# SAM9X60 device description
Architecture: ARM926EJS; Family: SAM9; Series: SAM9X
Registers are 32-bit, read-write, no defined reset value unless marked. A register's access mark holds for its fields unless they carry their own. Offsets are from the block's base; [hi:lo] are bit positions.

## SYSCWP — External Interrupt Controller
Instances: SYSCWP 0xFFFFFEDC
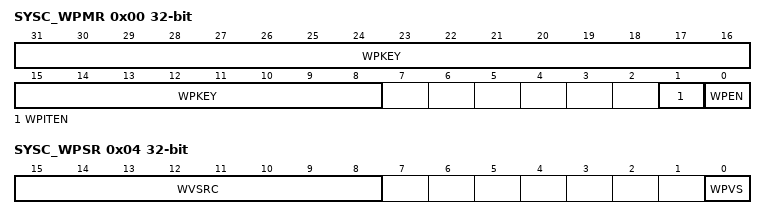
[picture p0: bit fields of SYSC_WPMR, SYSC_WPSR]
0x00 SYSC_WPMR — Write Protection Mode Register
  [31:8] WPKEY — Write Protection Key
    0x535943=PASSWD (Writing any other value in this field aborts the write operation of the WPEN and WPITEN bits. Always reads as 0.)
  [1] WPITEN — Write Protection RTC Interrupt Enable
  [0] WPEN — Write Protection Enable
0x04 SYSC_WPSR ro — Write Protection Status Register
  [15:8] WVSRC — Write Violation Source
  [0] WPVS — Write Protection Register Violation Status

## TRNG — True Random Number Generator
Instances: TRNG 0xF0030000
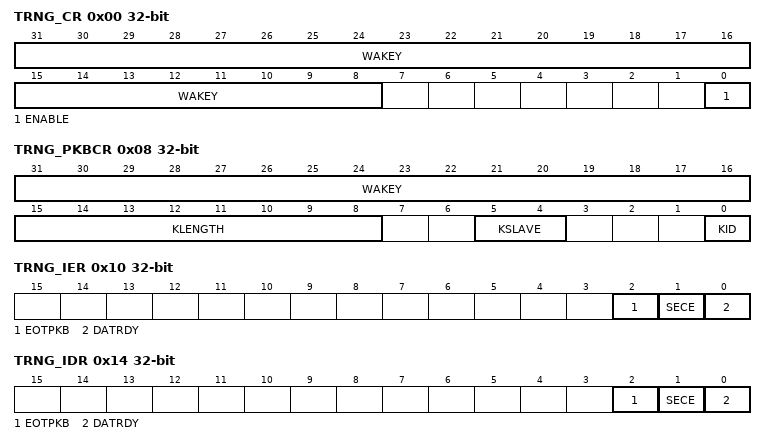
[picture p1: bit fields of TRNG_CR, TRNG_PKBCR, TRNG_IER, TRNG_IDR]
0x00 TRNG_CR wo — Control Register
  [31:8] WAKEY — Register Write Access Key
    0x524E47=PASSWD (Writing any other value in this field aborts the write operation.)
  [0] ENABLE — Enable TRNG to Provide Random Values
0x04 TRNG_MR — Mode Register
  [0] HALFR — Half Rate Enable
0x08 TRNG_PKBCR wo — Private Key Bus Control Register
  [31:16] WAKEY — Register Write Access Key
    0x524B=PASSWD (Writing any other value in this field aborts the write operation.)
  [15:8] KLENGTH — Key Length
  [5:4] KSLAVE — Key Bus Slave
    0=TDES_ID (Selects the TDES.); 1=AES_ID (Selects the AES.); 2=OTPC_ID (Selects the OTPC.)
  [0] KID — Key ID (Must be Always Written to 0)
0x10 TRNG_IER wo — Interrupt Enable Register
  [2] EOTPKB — End Of Transfer on Private Key Bus Interrupt Enable
  [1] SECE — Security and/or Safety Event Interrupt Enable
  [0] DATRDY — Data Ready Interrupt Enable
0x14 TRNG_IDR wo — Interrupt Disable Register
  [2] EOTPKB — End Of Transfer on Private Key Bus Interrupt Disable
  [1] SECE — Security and/or Safety Event Interrupt Disable
  [0] DATRDY — Data Ready Interrupt Disable
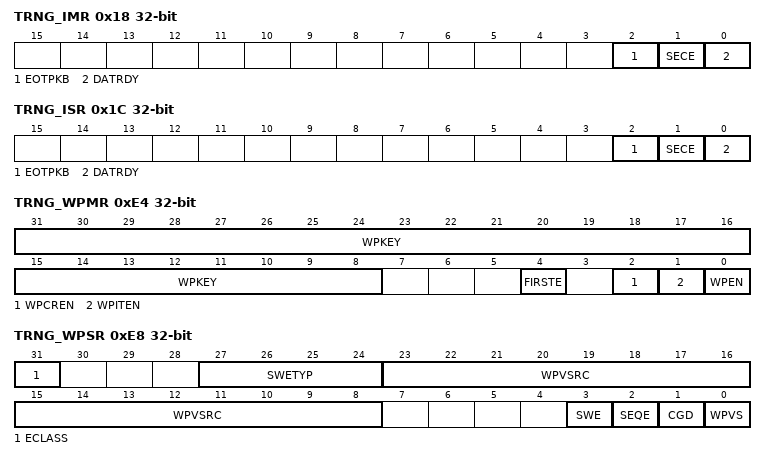
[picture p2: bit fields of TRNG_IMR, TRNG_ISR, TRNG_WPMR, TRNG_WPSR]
0x18 TRNG_IMR ro — Interrupt Mask Register
  [2] EOTPKB — End Of Transfer on Private Key Bus Interrupt Mask
  [1] SECE — Security and/or Safety Event Interrupt Mask
  [0] DATRDY — Data Ready Interrupt Mask
0x1C TRNG_ISR ro — Interrupt Status Register
  [2] EOTPKB — End Of Transfer on Private Key Bus (cleared on read)
  [1] SECE — Security and/or Safety Event (cleared on read)
  [0] DATRDY — Data Ready (cleared on read)
0x50 TRNG_ODATA ro — Output Data Register
  [31:0] ODATA — Output Data
0xE4 TRNG_WPMR — Write Protection Mode Register
  [31:8] WPKEY — Write Protection Key
    0x524E47=PASSWD (Writing any other value in this field aborts the write operation of bits WPEN, WPITEN and WPCREN. Always reads as 0.)
  [4] FIRSTE — First Error Report Enable
  [2] WPCREN — Write Protection Control Enable
  [1] WPITEN — Write Protection Interrupt Enable
  [0] WPEN — Write Protection Enable
0xE8 TRNG_WPSR ro — Write Protection Status Register
  [31] ECLASS — Software Error Class (cleared on read)
    0=WARNING (An abnormal access that does not affect system functionality.); 1=ERROR (Reading TRNG_ODATA when TRNG was disabled or TRNG used for private key bus transfer. TRNG does not provide a random value. Writing to the PKB_CTRL register while a private key bus transfer is ongoing does not launch a new private key bus transfer.)
  [27:24] SWETYP — Software Error Type (cleared on read)
    0=READ_WO (TRNG is enabled and a write-only register has been read (Warning).); 1=WRITE_RO (TRNG is enabled and a write access has been performed on a read-only register (Warning).); 2=UNDEF_RW (Access to an undefined address.); 3=TRNG_DIS (The TRNG_ODATA register was read when TRNG was disabled or TRNG used for private key bus transfer (Error).); 4=PKB_BUSY (A write access to the PKB_CTRL register has been attempted during a private key bus transfer (Error).)
  [23:8] WPVSRC — Write Protection Violation Source (cleared on read)
  [3] SWE — Software Control Error (cleared on read)
  [2] SEQE — Internal Sequencer Error (cleared on read)
  [1] CGD — Clock Glitch Detected (cleared on read)
  [0] WPVS — Write Protection Violation Status (cleared on read)
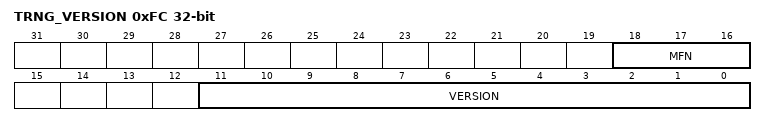
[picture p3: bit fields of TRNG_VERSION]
0xFC TRNG_VERSION ro — Version Register
  [18:16] MFN — Metal Fix Number
  [11:0] VERSION — Version of the Hardware Module

## WDT — Watchdog Timer
Instances: WDT 0xFFFFFF80
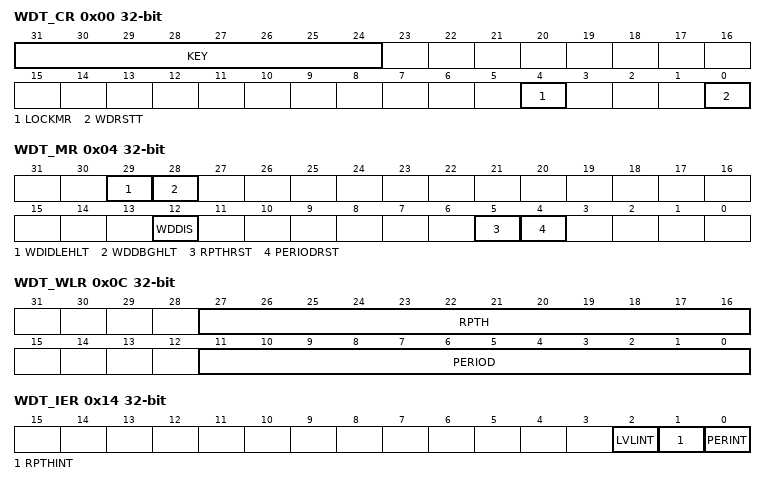
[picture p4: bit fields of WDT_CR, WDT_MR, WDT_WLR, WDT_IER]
0x00 WDT_CR wo — Control Register
  [31:24] KEY — Password
    165=PASSWD (Writing any other value in this field aborts the write operation.)
  [4] LOCKMR — Lock Mode Register Write Access
  [0] WDRSTT — Watchdog Restart
0x04 WDT_MR — Mode Register
  [29] WDIDLEHLT — Watchdog Idle Halt
  [28] WDDBGHLT — Watchdog Debug Halt
  [12] WDDIS — Watchdog Disable
  [5] RPTHRST — Minimum Restart Period
  [4] PERIODRST — Period Reset
0x08 WDT_VR ro — Value Register
  [11:0] COUNTER — Watchdog Down Counter Value
0x0C WDT_WLR — Window Level Register
  [27:16] RPTH — Repeat Threshold
  [11:0] PERIOD — Watchdog Period
0x10 WDT_ILR — Interrupt Level Register
  [11:0] LVLTH — Level Threshold
0x14 WDT_IER wo — Interrupt Enable Register
  [2] LVLINT — Interrupt Level Threshold Interrupt Enable
  [1] RPTHINT — Repeat Threshold Interrupt Enable
  [0] PERINT — Period Interrupt Enable
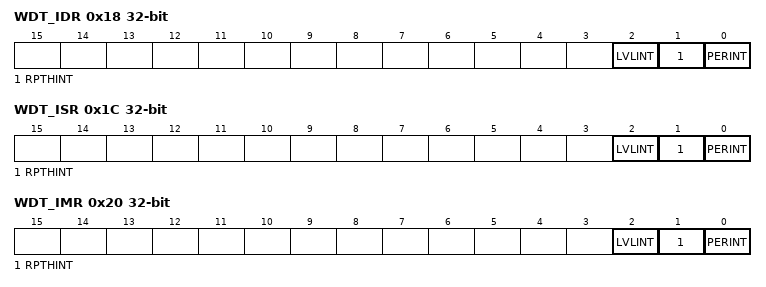
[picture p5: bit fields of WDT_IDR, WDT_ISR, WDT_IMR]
0x18 WDT_IDR wo — Interrupt Disable Register
  [2] LVLINT — Interrupt Level Threshold Interrupt Disable
  [1] RPTHINT — Repeat Threshold Interrupt Disable
  [0] PERINT — Period Interrupt Disable
0x1C WDT_ISR ro — Interrupt Status Register
  [2] LVLINT — Interrupt Level Threshold Interrupt Status (cleared on read)
  [1] RPTHINT — Repeat Threshold Interrupt Status (cleared on read)
  [0] PERINT — Period Interrupt Status (cleared on read)
0x20 WDT_IMR ro — Interrupt Mask Register
  [2] LVLINT — Interrupt Level Threshold Interrupt Mask
  [1] RPTHINT — Repeat Threshold Interrupt Mask
  [0] PERINT — Period Interrupt Mask
